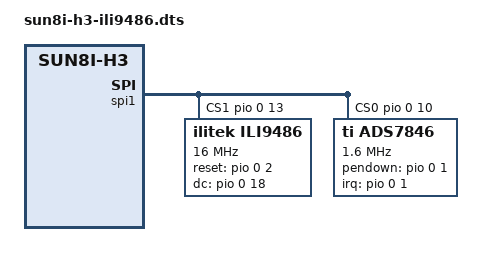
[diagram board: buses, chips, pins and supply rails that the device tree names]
/dts-v1/;
/plugin/;

/ {
    compatible = "allwinner,sun8i-h3";

	fragment@0 {
		target = <&spi1>;
		__overlay__ {
			num-cs = <2>;
			cs-gpios = <&pio 0 10 0>,
					   <&pio 0 13 0>;
			status = "okay";
			#address-cells = <1>;
			#size-cells = <0>;

			ili9486: ili9486@0{
				compatible = "ilitek,ili9486";
				reg = <1>;
				spi-max-frequency = <16000000>;
				txbuflen = <32768>;
				rotate = <90>;
				bgr = <0>;
				fps = <30>;
				buswidth = <8>;
				regwidth = <16>;
				reset-gpios = <&pio 0 2 0>;
				dc-gpios = <&pio 0 18 0>;
				debug = <1>;
				init = <0x10000f1 0x36 0x04 0x00 0x3c 0x0f 0x8f 0x10000f2 0x18 0xa3 0x12 0x02 0xb2 0x12 0xff 0x10 0x00 0x10000f8 0x21 0x04 0x10000f9 0x00 0x08 0x1000036 0x08 0x10000b4 0x00 0x10000c1 0x41 0x10000c5 0x00 0x91 0x80 0x00 0x10000e0 0x0f 0x1f 0x1c 0x0c 0x0f 0x08 0x48 0x98 0x37 0x0a 0x13 0x04 0x11 0x0d 0x00 0x10000e1 0x0f 0x32 0x2e 0x0b 0x0d 0x05 0x47 0x75 0x37 0x06 0x10 0x03 0x24 0x20 0x00 0x100003a 0x55 0x1000011 0x1000036 0x28 0x20000ff 0x1000029>;
			};
		};
	};

	fragment@1 {
	target = <&spi1>;
	__overlay__ {
		#address-cells = <1>;
		#size-cells = <0>;
		status = "okay";
		ads7846@0 {
			compatible = "ti,ads7846";
			reg = <0>; 
			status = "okay";
			spi-max-frequency = <1600000>;
			interrupt-parent = <&pio>;
			interrupts = <0 1 2>; /* PA1 IRQ_TYPE_EDGE_FALLING */
			pendown-gpio = <&pio 0 1 0>; /* PA1 */

			/* driver defaults, optional */
			ti,x-min = /bits/ 16 <0>;
			ti,y-min = /bits/ 16 <0>;
			ti,x-max = /bits/ 16 <0x0FFF>;
			ti,y-max = /bits/ 16 <0x0FFF>;
			ti,pressure-min = /bits/ 16 <0>;
			ti,pressure-max = /bits/ 16 <0xFFFF>;
			ti,x-plate-ohms = /bits/ 16 <400>;
			ti,swap-xy = <1>;
		};
	};
	};


};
